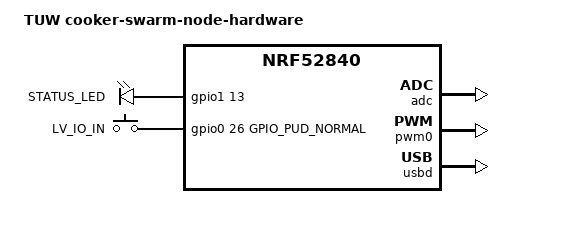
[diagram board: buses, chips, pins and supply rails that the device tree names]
/*
 * Copyright (c) 2017 Linaro Limited
 *
 * SPDX-License-Identifier: Apache-2.0
 */

/dts-v1/;
#include <nordic/nrf52840_qiaa.dtsi>

/ {
	model = "TUW cooker-swarm-node-hardware";
	compatible = "nordic,nrf52840-qiaa",
			   "nordic,nrf52840";

	chosen {
		zephyr,sram = &sram0;
		zephyr,flash = &flash0;
		zephyr,code-partition = &slot0_partition;
	};

	leds {
		compatible = "gpio-leds";
		led0: led_0 {
		  gpios = <&gpio1 13 0>;
		  label = "STATUS_LED";
	  	};
	};

	gpio_keys {
		compatible = "gpio-keys";
		lv_io_in: button_0 {
			gpios = <&gpio0 26 GPIO_PUD_NORMAL>;
			label = "LV_IO_IN";
		};
	};

	/* These aliases are provided for compatibility with samples */
	aliases {
		led0 = &led0;
	};
};

&adc {
	status = "okay";
};

&gpiote {
	status = "okay";
};

&gpio0 {
	status = "okay";
};

&gpio1 {
	status = "okay";
};

&pwm0 {
	status = "okay";
	ch0-pin = <45>;	// status LED
	ch0-inverted;
	ch1-pin = <8>;	// power out
	ch1-inverted;
};

&flash0 {
	/*
	 * For more information, see:
	 * http://docs.zephyrproject.org/latest/guides/dts/index.html#flash-partitions
	 */
	partitions {
		compatible = "fixed-partitions";
		#address-cells = <1>;
		#size-cells = <1>;

		boot_partition: partition@0 {
			label = "mcuboot";
			reg = <0x000000000 0x0000C000>;
		};
		slot0_partition: partition@c000 {
			label = "image-0";
			reg = <0x0000C000 0x000067000>;
		};
		slot1_partition: partition@73000 {
			label = "image-1";
			reg = <0x00073000 0x000067000>;
		};
		scratch_partition: partition@da000 {
			label = "image-scratch";
			reg = <0x000da000 0x0001e000>;
		};

		/*
		 * The flash starting at 0x000f8000 and ending at
		 * 0x000fffff is reserved for use by the application.
		 */

		/* Storage partition will be used by FCB/NFFS/NVS if enabled. */
		storage_partition: partition@f8000 {
			label = "storage";
			reg = <0x000f8000 0x00008000>;
		};
	};
};

&usbd {
	compatible = "nordic,nrf-usbd";
	status = "okay";
};
